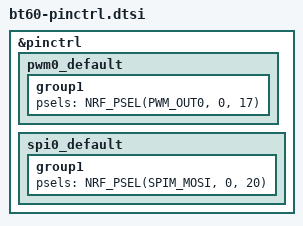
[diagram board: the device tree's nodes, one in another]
&pinctrl {
  pwm0_default: pwm0_default {
    group1 {
      psels = <NRF_PSEL(PWM_OUT0, 0, 17)>;
    };
  };
	spi0_default: spi0_default {
		group1 {
			psels = <NRF_PSEL(SPIM_MOSI, 0, 20)>;
		};
	};
};
